# STM32F730x register map
File version: 1.1
CPU: CM7 r0p1, little endian, MPU, FPU, 4 interrupt priority bits
Registers are 32-bit, read-write, reset 0x0 unless marked. A register's access mark holds for its fields unless they carry their own. Offsets are from the block's base; [hi:lo] are bit positions; {n}, {i} and the like mark numbered series.

## GPIOH — General-purpose I/Os
Base 0x40021C00
Same registers: GPIOC 0x40020800, GPIOD 0x40020C00, GPIOE 0x40021000, GPIOF 0x40021400, GPIOG 0x40021800, GPIOI 0x40022000
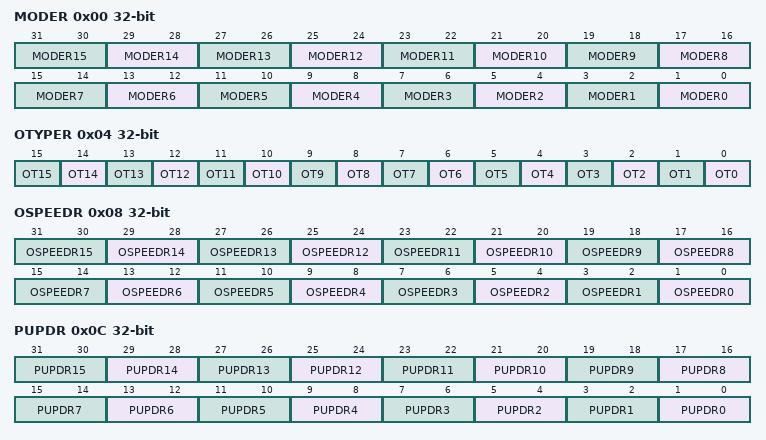
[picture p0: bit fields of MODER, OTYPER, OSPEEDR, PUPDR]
0x00 MODER — GPIO port mode register
  [2n+1:2n] MODER{n} (n=0..15) — Port x configuration bits (y = 0..15)
0x04 OTYPER — GPIO port output type register
  [n] OT{n} (n=0..15) — Port x configuration bits (y = 0..15)
0x08 OSPEEDR — GPIO port output speed register
  [2n+1:2n] OSPEEDR{n} (n=0..15) — Port x configuration bits (y = 0..15)
0x0C PUPDR — GPIO port pull-up/pull-down register
  [2n+1:2n] PUPDR{n} (n=0..15) — Port x configuration bits (y = 0..15)
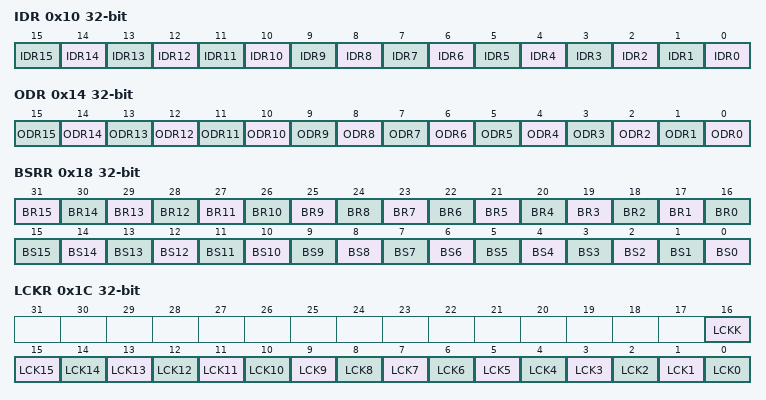
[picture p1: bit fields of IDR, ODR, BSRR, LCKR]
0x10 IDR ro — GPIO port input data register
  [n] IDR{n} (n=0..15) — Port input data (y = 0..15)
0x14 ODR — GPIO port output data register
  [n] ODR{n} (n=0..15) — Port output data (y = 0..15)
0x18 BSRR wo — GPIO port bit set/reset register
  [n+16] BR{n} (n=1..15) — Port x reset bit y (y = 0..15)
  [16] BR0 — Port x set bit y (y= 0..15)
  [n] BS{n} (n=0..15) — Port x set bit y (y= 0..15)
0x1C LCKR — GPIO port configuration lock register
  [16] LCKK — Port x lock bit y (y= 0..15)
  [n] LCK{n} (n=0..15) — Port x lock bit y (y= 0..15)
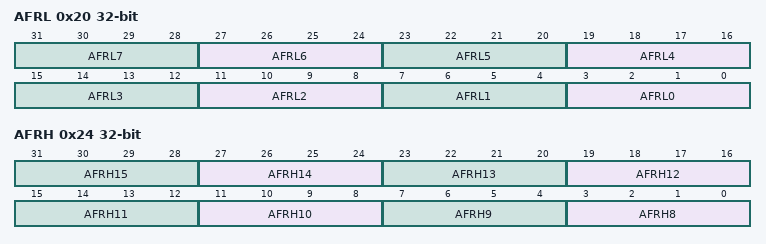
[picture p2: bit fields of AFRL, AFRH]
0x20 AFRL — GPIO alternate function lowregister
  [4n+3:4n] AFRL{n} (n=0..7) — Alternate function selection for port x bit y (y = 0..7)
0x24 AFRH — GPIO alternate function high register
  [4n-29:4n-32] AFRH{n} (n=8..15) — Alternate function selection for port x bit y (y = 8..15)

## GPIOB — General-purpose I/Os
Base 0x40020400
Registers as GPIOH; these are added or differ:
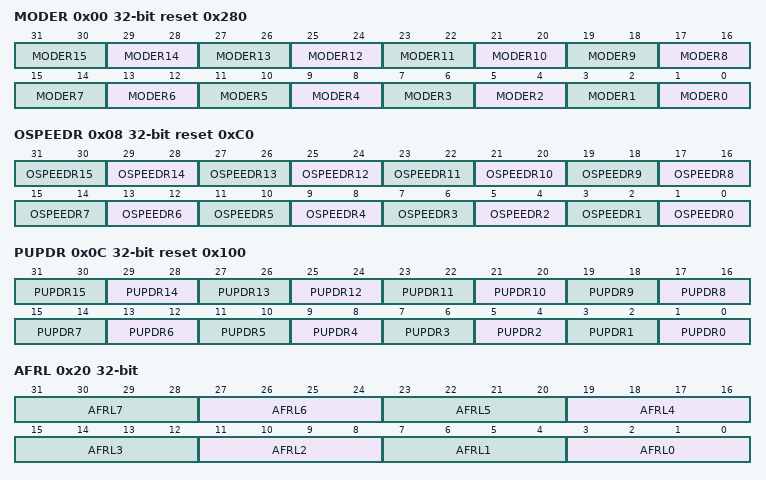
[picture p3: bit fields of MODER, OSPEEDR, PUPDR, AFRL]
0x00 MODER reset 0x280 — GPIO port mode register
  [2n+1:2n] MODER{n} (n=0..15) — Port x configuration bits (y = 0..15)
0x08 OSPEEDR reset 0xC0 — GPIO port output speed register
  [2n+1:2n] OSPEEDR{n} (n=0..15) — Port x configuration bits (y = 0..15)
0x0C PUPDR reset 0x100 — GPIO port pull-up/pull-down register
  [2n+1:2n] PUPDR{n} (n=0..15) — Port x configuration bits (y = 0..15)
0x20 AFRL — GPIO alternate function low register
  [4n+3:4n] AFRL{n} (n=0..7) — Alternate function selection for port x bit y (y = 0..7)

## GPIOA — General-purpose I/Os
Base 0x40020000
Registers as GPIOB; these are added or differ:
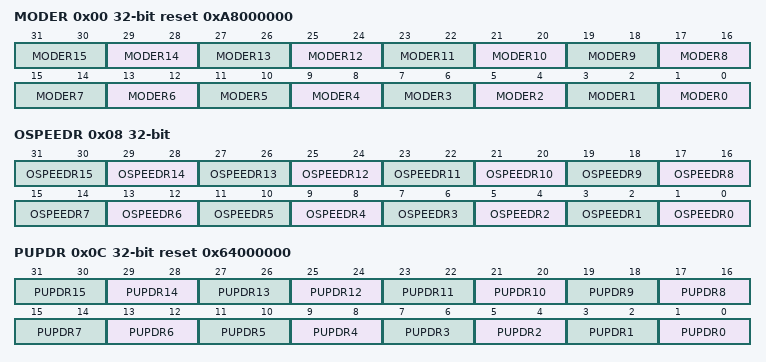
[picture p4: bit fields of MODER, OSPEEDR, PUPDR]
0x00 MODER reset 0xA8000000 — GPIO port mode register
  [2n+1:2n] MODER{n} (n=0..15) — Port x configuration bits (y = 0..15)
0x08 OSPEEDR — GPIO port output speed register
  [2n+1:2n] OSPEEDR{n} (n=0..15) — Port x configuration bits (y = 0..15)
0x0C PUPDR reset 0x64000000 — GPIO port pull-up/pull-down register
  [2n+1:2n] PUPDR{n} (n=0..15) — Port x configuration bits (y = 0..15)

## TIM13 — General-purpose-timers
Base 0x40001C00
Same registers: TIM14 0x40002000, TIM10 0x40014400, TIM11 0x40014800
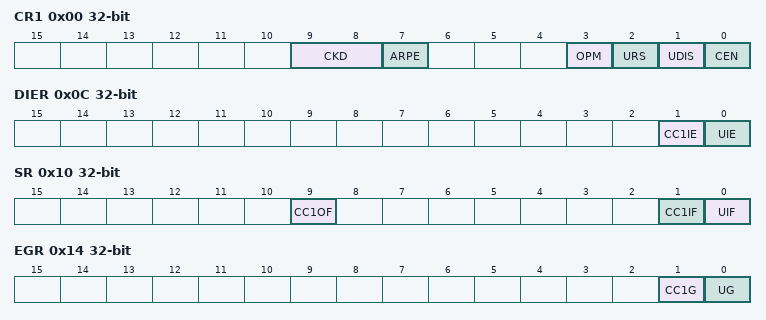
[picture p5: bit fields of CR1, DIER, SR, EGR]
0x00 CR1 — control register 1
  [9:8] CKD — Clock division
  [7] ARPE — Auto-reload preload enable
  [3] OPM — One-pulse mode
  [2] URS — Update request source
  [1] UDIS — Update disable
  [0] CEN — Counter enable
0x08 SMCR ro — slave mode control register
  [31:0] Res
0x0C DIER — DMA/Interrupt enable register
  [1] CC1IE — Capture/Compare 1 interrupt enable
  [0] UIE — Update interrupt enable
0x10 SR — status register
  [9] CC1OF — Capture/Compare 1 overcapture flag
  [1] CC1IF — Capture/compare 1 interrupt flag
  [0] UIF — Update interrupt flag
0x14 EGR wo — event generation register
  [1] CC1G — Capture/compare 1 generation
  [0] UG — Update generation
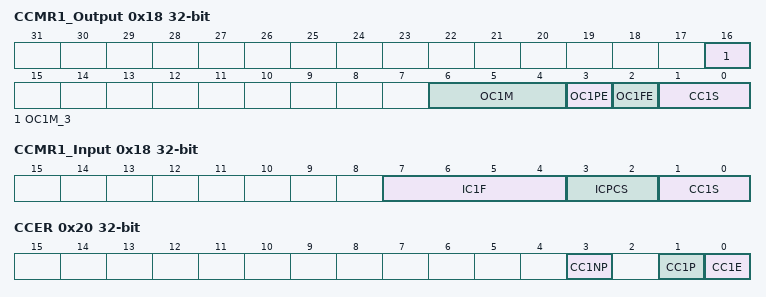
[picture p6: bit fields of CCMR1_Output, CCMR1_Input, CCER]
0x18 CCMR1_Output — capture/compare mode register 1 (output mode)
  [16] OC1M_3 — Output Compare 1 mode - bit 3
  [6:4] OC1M — Output Compare 1 mode
  [3] OC1PE — Output Compare 1 preload enable
  [2] OC1FE — Output Compare 1 fast enable
  [1:0] CC1S — Capture/Compare 1 selection
0x18 CCMR1_Input (alternate view of CCMR1_Output) — capture/compare mode register 1 (input mode)
  [7:4] IC1F — Input capture 1 filter
  [3:2] ICPCS — Input capture 1 prescaler
  [1:0] CC1S — Capture/Compare 1 selection
0x20 CCER — capture/compare enable register
  [3] CC1NP — Capture/Compare 1 output Polarity
  [1] CC1P — Capture/Compare 1 output Polarity
  [0] CC1E — Capture/Compare 1 output enable
0x24 CNT — counter
  [15:0] CNT — counter value
0x28 PSC — prescaler
  [15:0] PSC — Prescaler value
0x2C ARR — auto-reload register
  [15:0] ARR — Auto-reload value
0x34 CCR1 — capture/compare register 1
  [15:0] CCR1 — Capture/Compare 1 value
0x50 OR — option register
  [1:0] TI1_RMP — TIM11 Input 1 remapping capability
